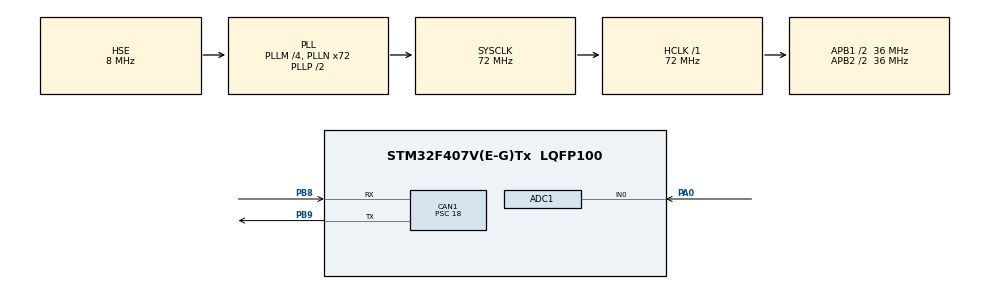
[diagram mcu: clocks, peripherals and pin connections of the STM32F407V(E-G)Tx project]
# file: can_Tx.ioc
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ADC1.Channel-2\#ChannelRegularConversion=ADC_CHANNEL_0
ADC1.NbrOfConversionFlag=1
ADC1.Rank-2\#ChannelRegularConversion=1
ADC1.SamplingTime-2\#ChannelRegularConversion=ADC_SAMPLETIME_3CYCLES
ADC1.master=1
CAN1.BS1=CAN_BS1_2TQ
CAN1.CalculateBaudRate=500000
CAN1.CalculateTimeBit=2000
CAN1.CalculateTimeQuantum=500.0
CAN1.Mode=CAN_MODE_NORMAL
CAN1.Prescaler=18
CAN1.SJW=CAN_SJW_1TQ
Mcu.Family=STM32F4
Mcu.Name=STM32F407V(E-G)Tx
Mcu.Package=LQFP100
NVIC.CAN1_RX0_IRQn=true\:0\:0\:false\:false\:true\:true\:true\:true
NVIC.PriorityGroup=NVIC_PRIORITYGROUP_0
PA0-WKUP.Signal=ADCx_IN0
PB8.Mode=CAN_Activate
PB8.Signal=CAN1_RX
PB9.Mode=CAN_Activate
PB9.Signal=CAN1_TX
PH0-OSC_IN.Mode=HSE-External-Oscillator
PH0-OSC_IN.Signal=RCC_OSC_IN
PH1-OSC_OUT.Mode=HSE-External-Oscillator
PH1-OSC_OUT.Signal=RCC_OSC_OUT
ProjectManager.HeapSize=0x200
ProjectManager.StackSize=0x400
ProjectManager.TargetToolchain=STM32CubeIDE
RCC.48MHZClocksFreq_Value=20571428.57142857
RCC.AHBFreq_Value=72000000
RCC.APB1CLKDivider=RCC_HCLK_DIV2
RCC.APB1Freq_Value=36000000
RCC.APB1TimFreq_Value=72000000
RCC.APB2CLKDivider=RCC_HCLK_DIV2
RCC.APB2Freq_Value=36000000
RCC.APB2TimFreq_Value=72000000
RCC.CortexFreq_Value=72000000
RCC.HCLKFreq_Value=72000000
RCC.HSE_VALUE=8000000
RCC.HSI_VALUE=16000000
RCC.LSE_VALUE=32768
RCC.PLLM=4
RCC.PLLN=72
RCC.PLLQ=7
RCC.PLLSourceVirtual=RCC_PLLSOURCE_HSE
RCC.SYSCLKFreq_VALUE=72000000
RCC.SYSCLKSource=RCC_SYSCLKSOURCE_PLLCLK
RCC.VCOOutputFreq_Value=144000000
SH.ADCx_IN0.0=ADC1_IN0,IN0
board=STM32F407G-DISC1

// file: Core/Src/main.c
/* USER CODE BEGIN Header */
/**
  ******************************************************************************
  * @file           : main.c
  * @brief          : Main program body
  ******************************************************************************
  * @attention
  *
  * Copyright (c) 2024 STMicroelectronics.
  * All rights reserved.
  *
  * This software is licensed under terms that can be found in the LICENSE file
  * in the root directory of this software component.
  * If no LICENSE file comes with this software, it is provided AS-IS.
  *
  ******************************************************************************
  */
/* USER CODE END Header */
#include "main.h"

ADC_HandleTypeDef hadc1;

CAN_HandleTypeDef hcan1;

/* USER CODE BEGIN PV */
   uint8_t TxData[8] = {0};
   uint16_t moisture = 0;

/* USER CODE END PV */

void SystemClock_Config(void);
static void MX_GPIO_Init(void);
static void MX_CAN1_Init(void);
static void MX_ADC1_Init(void);

/* USER CODE BEGIN 0 */
CAN_RxHeaderTypeDef RxHeader;
uint8_t RxData[8];

void HAL_CAN_RxFifo0MsgPendingCallback(CAN_HandleTypeDef *hcan) {
	HAL_CAN_GetRxMessage(hcan, CAN_RX_FIFO0, &RxHeader, RxData);
	// process the message
}
/* USER CODE END 0 */

int main(void)
{

  /* MCU Configuration--------------------------------------------------------*/

  /* Reset of all peripherals, Initializes the Flash interface and the Systick. */
  HAL_Init();

  /* Configure the system clock */
  SystemClock_Config();

  /* Initialize all configured peripherals */
  MX_GPIO_Init();
  MX_CAN1_Init();
  MX_ADC1_Init();
  /* USER CODE BEGIN 2 */
  HAL_CAN_Start(&hcan1);
//  HAL_CAN_ActivateNotification(&hcan1, CAN_IT_RX_FIFO0_MSG_PENDING);

  // send first CAN message
//  CAN_TxHeaderTypeDef TxHeader1;
//  TxHeader1.DLC = 4;
//  TxHeader1.RTR = CAN_RTR_DATA;
//  TxHeader1.IDE = CAN_ID_STD;
//  TxHeader1.StdId = 0x0A9;
//  TxHeader1.ExtId = 0x0000;
//  TxHeader1.TransmitGlobalTime = DISABLE;
//  uint8_t TxData1[8] = "DESD";
//  uint32_t TxMailBox1;
//  if(HAL_CAN_AddTxMessage(&hcan1, &TxHeader1, TxData1, &TxMailBox1) != HAL_OK)
//	  Error_Handler();

  // send second CAN message
//  CAN_TxHeaderTypeDef TxHeader2;
//  TxHeader2.DLC = 7;
//  TxHeader2.RTR = CAN_RTR_DATA;
//  TxHeader2.IDE = CAN_ID_STD;
//  TxHeader2.StdId = 0x0AA;
//  TxHeader2.ExtId = 0x0000;
//  TxHeader2.TransmitGlobalTime = DISABLE;
//  uint8_t TxData2[8] = "SUNBEAM";
//  uint32_t TxMailBox2;
//  if(HAL_CAN_AddTxMessage(&hcan1, &TxHeader2, TxData2, &TxMailBox2) != HAL_OK)
//	  Error_Handler();

  // send third CAN message
//  CAN_TxHeaderTypeDef TxHeader3;
//  TxHeader3.DLC = 5;
//  TxHeader3.RTR = CAN_RTR_DATA;
//  TxHeader3.IDE = CAN_ID_STD;
//  TxHeader3.StdId = 0x0AC;
//  TxHeader3.ExtId = 0x0000;
//  TxHeader3.TransmitGlobalTime = DISABLE;
//  uint32_t TxMailBox3;
//  uint8_t TxData3[8] = "C-DAC";
//  if(HAL_CAN_AddTxMessage(&hcan1, &TxHeader3, TxData3, &TxMailBox3) != HAL_OK)
//	  Error_Handler();
  /* USER CODE END 2 */

  /* Infinite loop */
  /* USER CODE BEGIN WHILE */

  CAN_TxHeaderTypeDef TxHeader3;
  TxHeader3.DLC = 2;
  TxHeader3.RTR = CAN_RTR_DATA;
  TxHeader3.IDE = CAN_ID_STD;
  TxHeader3.StdId = 0x0AC;
  TxHeader3.ExtId = 0x0000;
  TxHeader3.TransmitGlobalTime = DISABLE;
  uint32_t TxMailBox3;

  while (1)
  {
    /* USER CODE END WHILE */

    /* USER CODE BEGIN 3 */
	    HAL_ADC_Start(&hadc1);
	  	HAL_ADC_PollForConversion(&hadc1, 20);
	  	moisture = HAL_ADC_GetValue(&hadc1);

	  	TxData[0] = moisture;
	  	TxData[1] = moisture >> 8;

	  	if(HAL_CAN_AddTxMessage(&hcan1, &TxHeader3, TxData, &TxMailBox3) != HAL_OK)
	  		  Error_Handler();

	  	HAL_Delay(30);
  }
  /* USER CODE END 3 */
}

void SystemClock_Config(void)
{
  RCC_OscInitTypeDef RCC_OscInitStruct = {0};
  RCC_ClkInitTypeDef RCC_ClkInitStruct = {0};

  /** Configure the main internal regulator output voltage
  */
  __HAL_RCC_PWR_CLK_ENABLE();
  __HAL_PWR_VOLTAGESCALING_CONFIG(PWR_REGULATOR_VOLTAGE_SCALE1);

  /** Initializes the RCC Oscillators according to the specified parameters
  * in the RCC_OscInitTypeDef structure.
  */
  RCC_OscInitStruct.OscillatorType = RCC_OSCILLATORTYPE_HSE;
  RCC_OscInitStruct.HSEState = RCC_HSE_ON;
  RCC_OscInitStruct.PLL.PLLState = RCC_PLL_ON;
  RCC_OscInitStruct.PLL.PLLSource = RCC_PLLSOURCE_HSE;
  RCC_OscInitStruct.PLL.PLLM = 4;
  RCC_OscInitStruct.PLL.PLLN = 72;
  RCC_OscInitStruct.PLL.PLLP = RCC_PLLP_DIV2;
  RCC_OscInitStruct.PLL.PLLQ = 7;
  if (HAL_RCC_OscConfig(&RCC_OscInitStruct) != HAL_OK)
  {
    Error_Handler();
  }

  /** Initializes the CPU, AHB and APB buses clocks
  */
  RCC_ClkInitStruct.ClockType = RCC_CLOCKTYPE_HCLK|RCC_CLOCKTYPE_SYSCLK
                              |RCC_CLOCKTYPE_PCLK1|RCC_CLOCKTYPE_PCLK2;
  RCC_ClkInitStruct.SYSCLKSource = RCC_SYSCLKSOURCE_PLLCLK;
  RCC_ClkInitStruct.AHBCLKDivider = RCC_SYSCLK_DIV1;
  RCC_ClkInitStruct.APB1CLKDivider = RCC_HCLK_DIV2;
  RCC_ClkInitStruct.APB2CLKDivider = RCC_HCLK_DIV2;

  if (HAL_RCC_ClockConfig(&RCC_ClkInitStruct, FLASH_LATENCY_2) != HAL_OK)
  {
    Error_Handler();
  }
}

static void MX_ADC1_Init(void)
{

  ADC_ChannelConfTypeDef sConfig = {0};

  /** Configure the global features of the ADC (Clock, Resolution, Data Alignment and number of conversion)
  */
  hadc1.Instance = ADC1;
  hadc1.Init.ClockPrescaler = ADC_CLOCK_SYNC_PCLK_DIV2;
  hadc1.Init.Resolution = ADC_RESOLUTION_12B;
  hadc1.Init.ScanConvMode = DISABLE;
  hadc1.Init.ContinuousConvMode = DISABLE;
  hadc1.Init.DiscontinuousConvMode = DISABLE;
  hadc1.Init.ExternalTrigConvEdge = ADC_EXTERNALTRIGCONVEDGE_NONE;
  hadc1.Init.ExternalTrigConv = ADC_SOFTWARE_START;
  hadc1.Init.DataAlign = ADC_DATAALIGN_RIGHT;
  hadc1.Init.NbrOfConversion = 1;
  hadc1.Init.DMAContinuousRequests = DISABLE;
  hadc1.Init.EOCSelection = ADC_EOC_SINGLE_CONV;
  if (HAL_ADC_Init(&hadc1) != HAL_OK)
  {
    Error_Handler();
  }

  /** Configure for the selected ADC regular channel its corresponding rank in the sequencer and its sample time.
  */
  sConfig.Channel = ADC_CHANNEL_0;
  sConfig.Rank = 1;
  sConfig.SamplingTime = ADC_SAMPLETIME_3CYCLES;
  if (HAL_ADC_ConfigChannel(&hadc1, &sConfig) != HAL_OK)
  {
    Error_Handler();
  }

}

static void MX_CAN1_Init(void)
{

  hcan1.Instance = CAN1;
  hcan1.Init.Prescaler = 18;
  hcan1.Init.Mode = CAN_MODE_NORMAL;
  hcan1.Init.SyncJumpWidth = CAN_SJW_1TQ;
  hcan1.Init.TimeSeg1 = CAN_BS1_2TQ;
  hcan1.Init.TimeSeg2 = CAN_BS2_1TQ;
  hcan1.Init.TimeTriggeredMode = DISABLE;
  hcan1.Init.AutoBusOff = DISABLE;
  hcan1.Init.AutoWakeUp = DISABLE;
  hcan1.Init.AutoRetransmission = DISABLE;
  hcan1.Init.ReceiveFifoLocked = DISABLE;
  hcan1.Init.TransmitFifoPriority = DISABLE;
  if (HAL_CAN_Init(&hcan1) != HAL_OK)
  {
    Error_Handler();
  }
  /* USER CODE BEGIN CAN1_Init 2 */

  CAN_FilterTypeDef FilterConfig;
  FilterConfig.SlaveStartFilterBank = 9; // CAN1-0 to 8, CAN2-9 to 27
  FilterConfig.FilterActivation = CAN_FILTER_ENABLE;
  FilterConfig.FilterBank = 5; // Use any Filter from 0 to 8
  FilterConfig.FilterScale = CAN_FILTERSCALE_32BIT; // Use a 32-bit filter
  FilterConfig.FilterMode = CAN_FILTERMODE_IDMASK;
  FilterConfig.FilterMaskIdHigh = 0xFF00;
  FilterConfig.FilterMaskIdLow = 0x0000;
  FilterConfig.FilterIdHigh = 0x1500;
  FilterConfig.FilterIdLow = 0x0000;
  FilterConfig.FilterFIFOAssignment = CAN_RX_FIFO0;

  if(HAL_CAN_ConfigFilter(&hcan1, &FilterConfig) != HAL_OK)
	  Error_Handler();
  /* USER CODE END CAN1_Init 2 */

}

static void MX_GPIO_Init(void)
{

  /* GPIO Ports Clock Enable */
  __HAL_RCC_GPIOH_CLK_ENABLE();
  __HAL_RCC_GPIOA_CLK_ENABLE();
  __HAL_RCC_GPIOB_CLK_ENABLE();

}

void Error_Handler(void)
{
  /* USER CODE BEGIN Error_Handler_Debug */
  /* User can add his own implementation to report the HAL error return state */
  __disable_irq();
  while (1)
  {
	  // Blink RED Led ...
  }
  /* USER CODE END Error_Handler_Debug */
}
